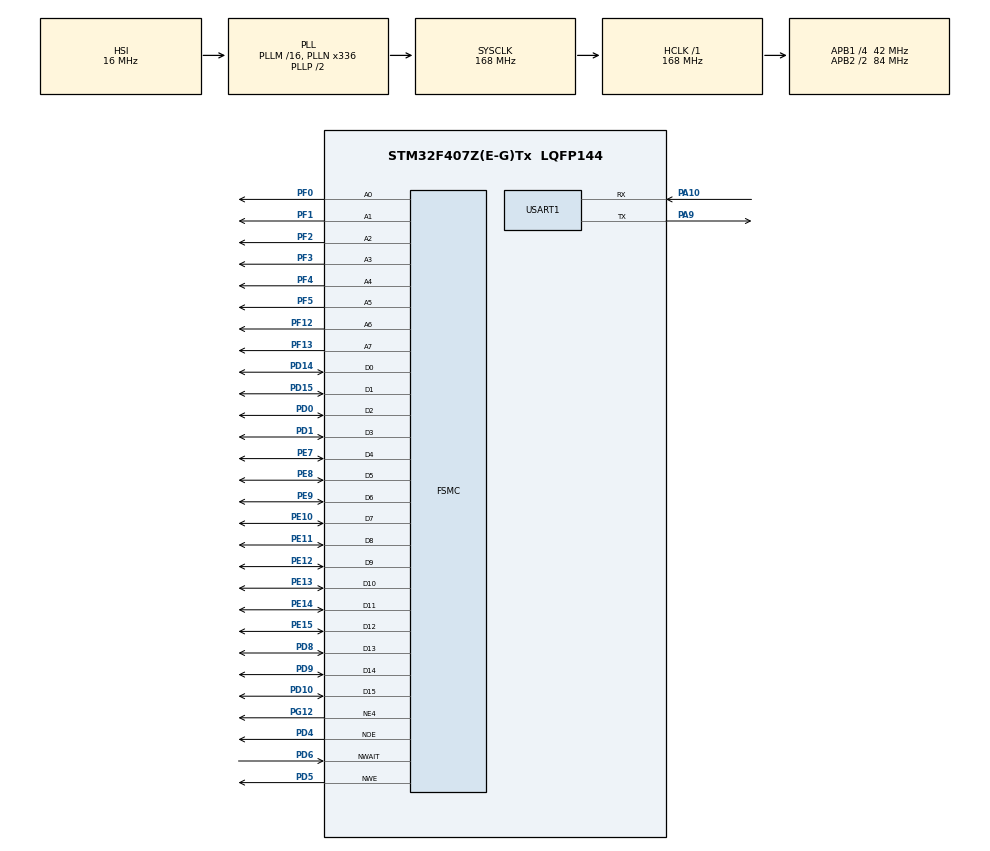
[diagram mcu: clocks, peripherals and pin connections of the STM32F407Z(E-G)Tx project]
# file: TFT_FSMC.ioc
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FSMC.DataSetupTime1=60
FSMC.ExtendedAddressSetupTime1=3
FSMC.ExtendedDataSetupTime1=3
FSMC.ExtendedMode1=FSMC_EXTENDED_MODE_ENABLE
FSMC.WaitSignalPolarity1=FSMC_WAIT_SIGNAL_POLARITY_LOW
FSMC.WriteOperation1=FSMC_WRITE_OPERATION_ENABLE
Mcu.Family=STM32F4
Mcu.Name=STM32F407Z(E-G)Tx
Mcu.Package=LQFP144
NVIC.PriorityGroup=NVIC_PRIORITYGROUP_4
PA10.Mode=Asynchronous
PA10.Signal=USART1_RX
PA9.Mode=Asynchronous
PA9.Signal=USART1_TX
PC14-OSC32_IN.Mode=LSE-External-Oscillator
PC14-OSC32_IN.Signal=RCC_OSC32_IN
PC15-OSC32_OUT.Mode=LSE-External-Oscillator
PC15-OSC32_OUT.Signal=RCC_OSC32_OUT
PD0.Signal=FSMC_D2_DA2
PD1.Signal=FSMC_D3_DA3
PD10.Signal=FSMC_D15_DA15
PD14.Signal=FSMC_D0_DA0
PD15.Signal=FSMC_D1_DA1
PD4.Signal=FSMC_NOE
PD5.Signal=FSMC_NWE
PD6.Signal=FSMC_NWAIT
PD8.Signal=FSMC_D13_DA13
PD9.Signal=FSMC_D14_DA14
PE10.Signal=FSMC_D7_DA7
PE11.Signal=FSMC_D8_DA8
PE12.Signal=FSMC_D9_DA9
PE13.Signal=FSMC_D10_DA10
PE14.Signal=FSMC_D11_DA11
PE15.Signal=FSMC_D12_DA12
PE7.Signal=FSMC_D4_DA4
PE8.Signal=FSMC_D5_DA5
PE9.Signal=FSMC_D6_DA6
PF0.Signal=FSMC_A0
PF1.Signal=FSMC_A1
PF12.Signal=FSMC_A6
PF13.Signal=FSMC_A7
PF2.Signal=FSMC_A2
PF3.Signal=FSMC_A3
PF4.Signal=FSMC_A4
PF5.Signal=FSMC_A5
PG12.Mode=NorPsramChipSelect4_1
PG12.Signal=FSMC_NE4
PH0-OSC_IN.Mode=HSE-External-Oscillator
PH0-OSC_IN.Signal=RCC_OSC_IN
PH1-OSC_OUT.Mode=HSE-External-Oscillator
PH1-OSC_OUT.Signal=RCC_OSC_OUT
ProjectManager.HeapSize=0x200
ProjectManager.StackSize=0x400
ProjectManager.TargetToolchain=MDK-ARM V5
RCC.48MHZClocksFreq_Value=84000000
RCC.AHBFreq_Value=168000000
RCC.APB1CLKDivider=RCC_HCLK_DIV4
RCC.APB1Freq_Value=42000000
RCC.APB1TimFreq_Value=84000000
RCC.APB2CLKDivider=RCC_HCLK_DIV2
RCC.APB2Freq_Value=84000000
RCC.APB2TimFreq_Value=168000000
RCC.CortexFreq_Value=168000000
RCC.HCLKFreq_Value=168000000
RCC.HSE_VALUE=25000000
RCC.HSI_VALUE=16000000
RCC.PLLN=336
RCC.SYSCLKFreq_VALUE=168000000
RCC.SYSCLKSource=RCC_SYSCLKSOURCE_PLLCLK
RCC.VCOOutputFreq_Value=336000000
SH.FSMC_A0.0=FSMC_A0,8b-a1
SH.FSMC_A1.0=FSMC_A1,8b-a1
SH.FSMC_A2.0=FSMC_A2,8b-a1
SH.FSMC_A3.0=FSMC_A3,8b-a1
SH.FSMC_A4.0=FSMC_A4,8b-a1
SH.FSMC_A5.0=FSMC_A5,8b-a1
SH.FSMC_A6.0=FSMC_A6,8b-a1
SH.FSMC_A7.0=FSMC_A7,8b-a1
SH.FSMC_D0_DA0.0=FSMC_D0,16b-d1
SH.FSMC_D10_DA10.0=FSMC_D10,16b-d1
SH.FSMC_D11_DA11.0=FSMC_D11,16b-d1
SH.FSMC_D12_DA12.0=FSMC_D12,16b-d1
SH.FSMC_D13_DA13.0=FSMC_D13,16b-d1
SH.FSMC_D14_DA14.0=FSMC_D14,16b-d1
SH.FSMC_D15_DA15.0=FSMC_D15,16b-d1
SH.FSMC_D1_DA1.0=FSMC_D1,16b-d1
SH.FSMC_D2_DA2.0=FSMC_D2,16b-d1
SH.FSMC_D3_DA3.0=FSMC_D3,16b-d1
SH.FSMC_D4_DA4.0=FSMC_D4,16b-d1
SH.FSMC_D5_DA5.0=FSMC_D5,16b-d1
SH.FSMC_D6_DA6.0=FSMC_D6,16b-d1
SH.FSMC_D7_DA7.0=FSMC_D7,16b-d1
SH.FSMC_D8_DA8.0=FSMC_D8,16b-d1
SH.FSMC_D9_DA9.0=FSMC_D9,16b-d1
SH.FSMC_NOE.0=FSMC_NOE,Sram1
SH.FSMC_NWAIT.0=FSMC_NWAIT,AsynchronousWait1
SH.FSMC_NWE.0=FSMC_NWE,Sram1
USART1.VirtualMode=VM_ASYNC
board=custom

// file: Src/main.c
/* USER CODE BEGIN Header */
/**
  ******************************************************************************
  * @file           : main.c
  * @brief          : Main program body
  ******************************************************************************
  * @attention
  *
  * <h2><center>&copy; Copyright (c) 2019 STMicroelectronics.
  * All rights reserved.</center></h2>
  *
  * This software component is licensed by ST under BSD 3-Clause license,
  * the "License"; You may not use this file except in compliance with the
  * License. You may obtain a copy of the License at:
  *                        opensource.org/licenses/BSD-3-Clause
  *
  ******************************************************************************
  */
/* USER CODE END Header */

#include "main.h"
#include "usart.h"
#include "gpio.h"
#include "fsmc.h"

/* USER CODE BEGIN Includes */
#include <stdio.h>
#include "tft_lcd.h"
/* USER CODE END Includes */

void SystemClock_Config(void);

int main(void)
{
  /* USER CODE BEGIN 1 */
	uint8_t i;
  /* USER CODE END 1 */

  /* MCU Configuration--------------------------------------------------------*/

  /* Reset of all peripherals, Initializes the Flash interface and the Systick. */
  HAL_Init();

  /* Configure the system clock */
  SystemClock_Config();

  /* Initialize all configured peripherals */
  MX_GPIO_Init();
  MX_FSMC_Init();
  MX_USART1_UART_Init();
  /* USER CODE BEGIN 2 */
	//HAL_Delay(50);
  /* USER CODE END 2 */

  /* Infinite loop */
  /* USER CODE BEGIN WHILE */
  while (1)
  {
		LCD_WR_REG(0xD3);
		for(i=0;i<4;i++)
		{
			printf("%x\r\n",LCD_RD_DATA());
		}
		HAL_Delay(300);
    /* USER CODE END WHILE */

  }
}

void SystemClock_Config(void)
{
  RCC_OscInitTypeDef RCC_OscInitStruct = {0};
  RCC_ClkInitTypeDef RCC_ClkInitStruct = {0};

  /** Configure the main internal regulator output voltage
  */
  __HAL_RCC_PWR_CLK_ENABLE();
  __HAL_PWR_VOLTAGESCALING_CONFIG(PWR_REGULATOR_VOLTAGE_SCALE1);
  /** Initializes the CPU, AHB and APB busses clocks
  */
  RCC_OscInitStruct.OscillatorType = RCC_OSCILLATORTYPE_HSI;
  RCC_OscInitStruct.HSIState = RCC_HSI_ON;
  RCC_OscInitStruct.HSICalibrationValue = RCC_HSICALIBRATION_DEFAULT;
  RCC_OscInitStruct.PLL.PLLState = RCC_PLL_ON;
  RCC_OscInitStruct.PLL.PLLSource = RCC_PLLSOURCE_HSI;
  RCC_OscInitStruct.PLL.PLLM = 16;
  RCC_OscInitStruct.PLL.PLLN = 336;
  RCC_OscInitStruct.PLL.PLLP = RCC_PLLP_DIV2;
  RCC_OscInitStruct.PLL.PLLQ = 4;
  if (HAL_RCC_OscConfig(&RCC_OscInitStruct) != HAL_OK)
  {
    Error_Handler();
  }
  /** Initializes the CPU, AHB and APB busses clocks
  */
  RCC_ClkInitStruct.ClockType = RCC_CLOCKTYPE_HCLK|RCC_CLOCKTYPE_SYSCLK
                              |RCC_CLOCKTYPE_PCLK1|RCC_CLOCKTYPE_PCLK2;
  RCC_ClkInitStruct.SYSCLKSource = RCC_SYSCLKSOURCE_PLLCLK;
  RCC_ClkInitStruct.AHBCLKDivider = RCC_SYSCLK_DIV1;
  RCC_ClkInitStruct.APB1CLKDivider = RCC_HCLK_DIV4;
  RCC_ClkInitStruct.APB2CLKDivider = RCC_HCLK_DIV2;

  if (HAL_RCC_ClockConfig(&RCC_ClkInitStruct, FLASH_LATENCY_5) != HAL_OK)
  {
    Error_Handler();
  }
}

/* USER CODE BEGIN 4 */
int fputc(int ch, FILE *f)
{
	while((USART1->SR&0X40)==0);//ѭ������,ֱ���������
	USART1->DR = (uint8_t) ch;
	return ch;
}
/* USER CODE END 4 */

void Error_Handler(void)
{
}

/************************ (C) COPYRIGHT STMicroelectronics *****END OF FILE****/
